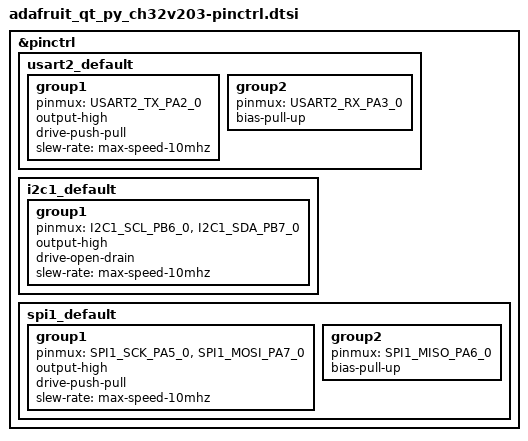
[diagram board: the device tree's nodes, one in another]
/*
 * SPDX-FileCopyrightText: Copyright (c) 2026 Perry Naseck, MIT Media Lab <pnaseck@media.mit.edu>
 * SPDX-License-Identifier: Apache-2.0
 */

#include <zephyr/dt-bindings/pinctrl/ch32v20x_30x-pinctrl.h>

&pinctrl {
	usart2_default: usart2_default {
		group1 {
			pinmux = <USART2_TX_PA2_0>;
			output-high;
			drive-push-pull;
			slew-rate = "max-speed-10mhz";
		};

		group2 {
			pinmux = <USART2_RX_PA3_0>;
			bias-pull-up;
		};
	};

	/omit-if-no-ref/ i2c1_default: i2c1_default {
		group1 {
			pinmux = <I2C1_SCL_PB6_0>, <I2C1_SDA_PB7_0>;
			output-high;
			drive-open-drain;
			slew-rate = "max-speed-10mhz";
		};
	};

	/omit-if-no-ref/ spi1_default: spi1_default {
		group1 {
			pinmux = <SPI1_SCK_PA5_0>, <SPI1_MOSI_PA7_0>;
			output-high;
			drive-push-pull;
			slew-rate = "max-speed-10mhz";
		};

		group2 {
			pinmux = <SPI1_MISO_PA6_0>;
			bias-pull-up;
		};
	};
};
